# MIMXRT1064 register map
Vendor: nxp.com; File version: 1.0
CPU: CM7 r0p1, little endian, MPU, FPU, VTOR, 4 interrupt priority bits
Registers are 32-bit, read-write, reset 0x0 unless marked. A register's access mark holds for its fields unless they carry their own. Offsets are from the block's base; [hi:lo] are bit positions; {n}, {i} and the like mark numbered series.

## CSI
Base 0x402BC000; register names take the prefix CSI_
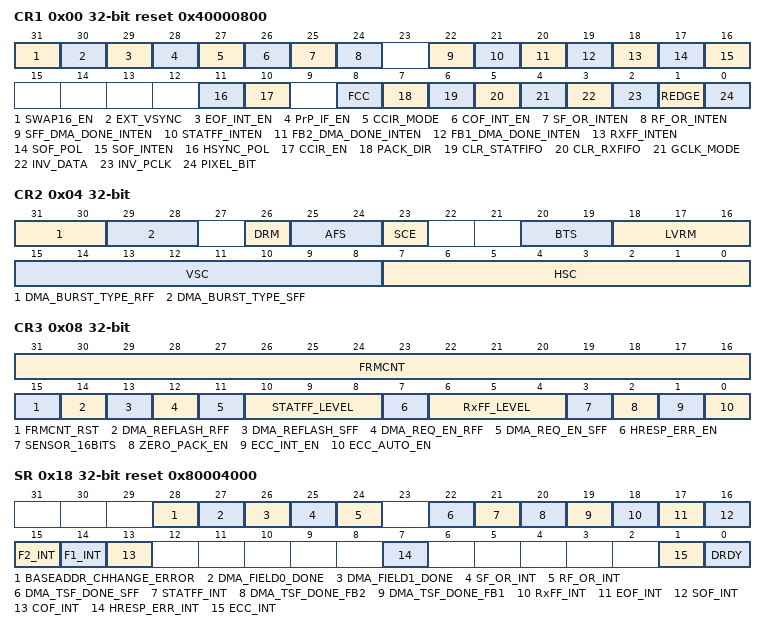
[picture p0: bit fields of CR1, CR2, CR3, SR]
0x00 CR1 reset 0x40000800 — CSI Control Register 1
  [31] SWAP16_EN — SWAP 16-Bit Enable
    0=Disable swapping; 1=Enable swapping
  [30] EXT_VSYNC — External VSYNC Enable
    0=Internal VSYNC mode; 1=External VSYNC mode
  [29] EOF_INT_EN — End-of-Frame Interrupt Enable. This bit enables and disables the EOF interrupt.
    0=EOF interrupt is disabled; 1=EOF interrupt is generated when RX count value is reached
  [28] PrP_IF_EN — CSI-PrP Interface Enable
    0=CSI to PrP bus is disabled; 1=CSI to PrP bus is enabled
  [27] CCIR_MODE — BT
    0=Progressive mode is selected; 1=Interlace mode is selected
  [26] COF_INT_EN — Change Of Image Field (COF) Interrupt Enable
    0=COF interrupt is disabled; 1=COF interrupt is enabled
  [25] SF_OR_INTEN — STAT FIFO Overrun Interrupt Enable. This bit enables the STATFIFO overrun interrupt.
    0=STATFIFO overrun interrupt is disabled; 1=STATFIFO overrun interrupt is enabled
  [24] RF_OR_INTEN — RxFIFO Overrun Interrupt Enable. This bit enables the RX FIFO overrun interrupt.
    0=RxFIFO overrun interrupt is disabled; 1=RxFIFO overrun interrupt is enabled
  [22] SFF_DMA_DONE_INTEN — STATFIFO DMA Transfer Done Interrupt Enable
    0=STATFIFO DMA Transfer Done interrupt disable; 1=STATFIFO DMA Transfer Done interrupt enable
  [21] STATFF_INTEN — STATFIFO Full Interrupt Enable. This bit enables the STAT FIFO interrupt.
    0=STATFIFO full interrupt disable; 1=STATFIFO full interrupt enable
  [20] FB2_DMA_DONE_INTEN — Frame Buffer2 DMA Transfer Done Interrupt Enable
    0=Frame Buffer2 DMA Transfer Done interrupt disable; 1=Frame Buffer2 DMA Transfer Done interrupt enable
  [19] FB1_DMA_DONE_INTEN — Frame Buffer1 DMA Transfer Done Interrupt Enable
    0=Frame Buffer1 DMA Transfer Done interrupt disable; 1=Frame Buffer1 DMA Transfer Done interrupt enable
  [18] RXFF_INTEN — RxFIFO Full Interrupt Enable. This bit enables the RxFIFO full interrupt.
    0=RxFIFO full interrupt disable; 1=RxFIFO full interrupt enable
  [17] SOF_POL — SOF Interrupt Polarity. This bit controls the condition that generates an SOF interrupt.
    0=SOF interrupt is generated on SOF falling edge; 1=SOF interrupt is generated on SOF rising edge
  [16] SOF_INTEN — Start Of Frame (SOF) Interrupt Enable. This bit enables the SOF interrupt.
    0=SOF interrupt disable; 1=SOF interrupt enable
  [11] HSYNC_POL — HSYNC Polarity Select
    0=HSYNC is active low; 1=HSYNC is active high
  [10] CCIR_EN — BT.656 Interface Enable. This bit selects the type of interface used.
    0=Traditional interface is selected; 1=BT.656 interface is selected
  [8] FCC — FIFO Clear Control
    0=Asynchronous FIFO clear is selected; 1=Synchronous FIFO clear is selected
  [7] PACK_DIR — Data Packing Direction
    0=Pack from LSB first. For image data, 0x11, 0x22, 0x33, 0x44, it will appear as 0x44332211 in RX FIFO. For stat data, 0xAAAA, 0xBBBB, it will appear as 0xBBBBAAAA in STAT FIFO.; 1=Pack from MSB first. For image data, 0x11, 0x22, 0x33, 0x44, it will appear as 0x11223344 in RX FIFO. For stat data, 0xAAAA, 0xBBBB, it will appear as 0xAAAABBBB in STAT FIFO.
  [6] CLR_STATFIFO — Asynchronous STATFIFO Clear
  [5] CLR_RXFIFO — Asynchronous RXFIFO Clear
  [4] GCLK_MODE — Gated Clock Mode Enable
    0=Non-gated clock mode. All incoming pixel clocks are valid. HSYNC is ignored.; 1=Gated clock mode. Pixel clock signal is valid only when HSYNC is active.
  [3] INV_DATA — Invert Data Input. This bit enables or disables internal inverters on the data lines.
    0=CSI_D[7:0] data lines are directly applied to internal circuitry; 1=CSI_D[7:0] data lines are inverted before applied to internal circuitry
  [2] INV_PCLK — Invert Pixel Clock Input
    0=CSI_PIXCLK is directly applied to internal circuitry; 1=CSI_PIXCLK is inverted before applied to internal circuitry
  [1] REDGE — Valid Pixel Clock Edge Select
    0=Pixel data is latched at the falling edge of CSI_PIXCLK; 1=Pixel data is latched at the rising edge of CSI_PIXCLK
  [0] PIXEL_BIT
    0=8-bit data for each pixel; 1=10-bit data for each pixel
0x04 CR2 — CSI Control Register 2
  [31:30] DMA_BURST_TYPE_RFF — Burst Type of DMA Transfer from RxFIFO. Selects the burst type of DMA transfer from RxFIFO.
    0bx0=INCR8; 1=INCR4; 3=INCR16
  [29:28] DMA_BURST_TYPE_SFF — Burst Type of DMA Transfer from STATFIFO. Selects the burst type of DMA transfer from STATFIFO.
    0bx0=INCR8; 1=INCR4; 3=INCR16
  [26] DRM — Double Resolution Mode. Controls size of statistics grid.
    0=Stats grid of 8 x 6; 1=Stats grid of 8 x 12
  [25:24] AFS — Auto Focus Spread. Selects which green pixels are used for auto-focus.
    0=Abs Diff on consecutive green pixels; 1=Abs Diff on every third green pixels; 0b1x=Abs Diff on every four green pixels
  [23] SCE — Skip Count Enable
    0=Skip count disable; 1=Skip count enable
  [20:19] BTS — Bayer Tile Start. Controls the Bayer pattern starting point.
    0=GR; 1=RG; 2=BG; 3=GB
  [18:16] LVRM — Live View Resolution Mode. Selects the grid size used for live view resolution.
    0=512 x 384; 1=448 x 336; 2=384 x 288; 3=384 x 256; 4=320 x 240; 5=288 x 216; 6=400 x 300
  [15:8] VSC — Vertical Skip Count. Contains the number of rows to skip. SCE must be 1, otherwise VSC is ignored.
    {v}=Number of rows to skip minus 1 (v=0..9)
  [7:0] HSC — Horizontal Skip Count
    {v}=Number of pixels to skip minus 1 (v=0..9)
0x08 CR3 — CSI Control Register 3
  [31:16] FRMCNT — Frame Counter
  [15] FRMCNT_RST — Frame Count Reset. Resets the Frame Counter. (Cleared automatically after reset is done)
    0=Do not reset; 1=Reset frame counter immediately
  [14] DMA_REFLASH_RFF — Reflash DMA Controller for RxFIFO
    0=No reflashing; 1=Reflash the embedded DMA controller
  [13] DMA_REFLASH_SFF — Reflash DMA Controller for STATFIFO
    0=No reflashing; 1=Reflash the embedded DMA controller
  [12] DMA_REQ_EN_RFF — DMA Request Enable for RxFIFO
    0=Disable the dma request; 1=Enable the dma request
  [11] DMA_REQ_EN_SFF — DMA Request Enable for STATFIFO
    0=Disable the dma request; 1=Enable the dma request
  [10:8] STATFF_LEVEL — STATFIFO Full Level
    0=4 Double words; 1=8 Double words; 2=12 Double words; 3=16 Double words; 4=24 Double words; 5=32 Double words; 6=48 Double words; 7=64 Double words
  [7] HRESP_ERR_EN — Hresponse Error Enable. This bit enables the hresponse (AHB protocol standard) error interrupt.
    0=Disable hresponse error interrupt; 1=Enable hresponse error interrupt
  [6:4] RxFF_LEVEL — RxFIFO Full Level
    0=4 Double words; 1=8 Double words; 2=16 Double words; 3=24 Double words; 4=32 Double words; 5=48 Double words; 6=64 Double words; 7=96 Double words
  [3] SENSOR_16BITS — 16-bit Sensor Mode
    0=Only one 8-bit sensor is connected; 1=One 16-bit sensor is connected
  [2] ZERO_PACK_EN — Dummy Zero Packing Enable
    0=Zero packing disabled; 1=Zero packing enabled
  [1] ECC_INT_EN — Error Detection Interrupt Enable
    0=No interrupt is generated when error is detected. Only the status bit ECC_INT is set.; 1=Interrupt is generated when error is detected
  [0] ECC_AUTO_EN — Automatic Error Correction Enable
    0=Auto Error correction is disabled; 1=Auto Error correction is enabled
0x0C STATFIFO ro — CSI Statistic FIFO Register
  [31:0] STAT — Static data from sensor
0x10 RFIFO ro — CSI RX FIFO Register
  [31:0] IMAGE — Received image data
0x14 RXCNT reset 0x9600 — CSI RX Count Register
  [21:0] RXCNT — RxFIFO Count
0x18 SR reset 0x80004000 — CSI Status Register
  [28] BASEADDR_CHHANGE_ERROR — When using base address switching enable, this bit will be 1 when switching occur before DMA complete
  [27] DMA_FIELD0_DONE — When DMA field 0 is complete, this bit will be set to 1(clear by writing 1).
  [26] DMA_FIELD1_DONE — When DMA field 1 is complete, this bit will be set to 1(clear by writing 1).
  [25] SF_OR_INT — STATFIFO Overrun Interrupt Status
    0=STATFIFO has not overflowed; 1=STATFIFO has overflowed
  [24] RF_OR_INT — RxFIFO Overrun Interrupt Status
    0=RXFIFO has not overflowed; 1=RXFIFO has overflowed
  [22] DMA_TSF_DONE_SFF — DMA Transfer Done from StatFIFO
    0=DMA transfer is not completed; 1=DMA transfer is completed
  [21] STATFF_INT — STATFIFO Full Interrupt Status
    0=STATFIFO is not full; 1=STATFIFO is full
  [20] DMA_TSF_DONE_FB2 — DMA Transfer Done in Frame Buffer2
    0=DMA transfer is not completed; 1=DMA transfer is completed
  [19] DMA_TSF_DONE_FB1 — DMA Transfer Done in Frame Buffer1
    0=DMA transfer is not completed; 1=DMA transfer is completed
  [18] RxFF_INT — RXFIFO Full Interrupt Status
    0=RxFIFO is not full; 1=RxFIFO is full
  [17] EOF_INT — End of Frame (EOF) Interrupt Status. Indicates when EOF is detected. (Cleared by writing 1)
    0=EOF is not detected; 1=EOF is detected
  [16] SOF_INT — Start of Frame Interrupt Status. Indicates when SOF is detected. (Cleared by writing 1)
    0=SOF is not detected; 1=SOF is detected
  [15] F2_INT — BT
    0=Field 2 of video is not detected; 1=Field 2 of video is about to start
  [14] F1_INT — BT
    0=Field 1 of video is not detected; 1=Field 1 of video is about to start
  [13] COF_INT — Change Of Field Interrupt Status
    0=Video field has no change; 1=Change of video field is detected
  [7] HRESP_ERR_INT — Hresponse Error Interrupt Status
    0=No hresponse error; 1=Hresponse error is detected
  [1] ECC_INT — BT
    0=No error detected; 1=Error is detected in BT.656 coding
  [0] DRDY — RXFIFO Data Ready
    0=No data (word) is ready; 1=At least 1 datum (word) is ready in RXFIFO
0x20 DMASA_STATFIFO — CSI DMA Start Address Register - for STATFIFO
  [31:2] DMA_START_ADDR_SFF — DMA Start Address for STATFIFO
0x24 DMATS_STATFIFO — CSI DMA Transfer Size Register - for STATFIFO
  [31:0] DMA_TSF_SIZE_SFF — DMA Transfer Size for STATFIFO
0x28 DMASA_FB1 — CSI DMA Start Address Register - for Frame Buffer1
  [31:2] DMA_START_ADDR_FB1 — DMA Start Address in Frame Buffer1
0x2C DMASA_FB2 — CSI DMA Transfer Size Register - for Frame Buffer2
  [31:2] DMA_START_ADDR_FB2 — DMA Start Address in Frame Buffer2
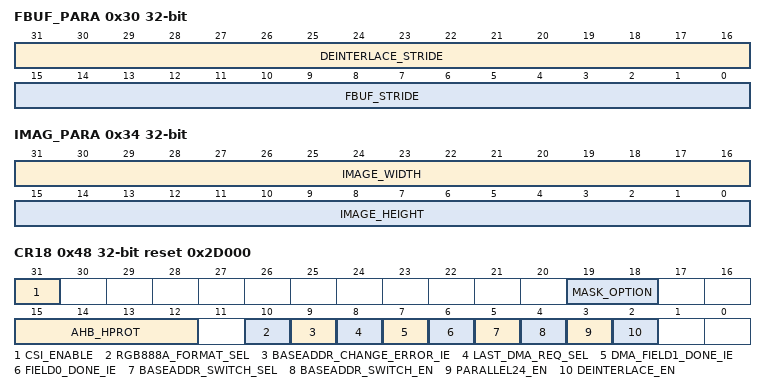
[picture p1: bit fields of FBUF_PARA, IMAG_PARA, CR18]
0x30 FBUF_PARA — CSI Frame Buffer Parameter Register
  [31:16] DEINTERLACE_STRIDE — DEINTERLACE_STRIDE is only used in the deinterlace mode
  [15:0] FBUF_STRIDE — Frame Buffer Parameter
0x34 IMAG_PARA — CSI Image Parameter Register
  [31:16] IMAGE_WIDTH — This field indicates the number of active pixel cycles per line
  [15:0] IMAGE_HEIGHT — Image Height. Indicates how many pixels in a column of the image from the sensor.
0x48 CR18 reset 0x2D000 — CSI Control Register 18
  [31] CSI_ENABLE — CSI global enable signal
  [19:18] MASK_OPTION — These bits used to choose the method to mask the CSI input.
    0=Writing to memory (OCRAM or external DDR) from first completely frame, when using this option, the CSI_ENABLE should be 1; 1=Writing to memory when CSI_ENABLE is 1; 2=Writing to memory from second completely frame, when using this option, the CSI_ENABLE should be 1; 3=Writing to memory when data comes in, not matter the CSI_ENABLE is 1 or 0
  [15:12] AHB_HPROT — Hprot value in AHB bus protocol.
  [10] RGB888A_FORMAT_SEL — Output is 32-bit format.
    0={8'h0, data[23:0]}; 1={data[23:0], 8'h0}
  [9] BASEADDR_CHANGE_ERROR_IE — Base address change error interrupt enable signal.
    0=Interrupt disabled; 1=Interrupt enabled
  [8] LAST_DMA_REQ_SEL — Choosing the last DMA request condition
    0=fifo_full_level; 1=hburst_length
  [7] DMA_FIELD1_DONE_IE — When in interlace mode, field 1 done interrupt enable.
    0=Interrupt disabled; 1=Interrupt enabled
  [6] FIELD0_DONE_IE — In interlace mode, field 0 means interrupt enabled.
    0=Interrupt disabled; 1=Interrupt enabled
  [5] BASEADDR_SWITCH_SEL — CSI 2 base addresses switching method. When using this bit, BASEADDR_SWITCH_EN is 1.
    0=Switching base address at the edge of the vsync; 1=Switching base address at the edge of the first data of each frame
  [4] BASEADDR_SWITCH_EN — When this bit is enabled, CSI DMA will switch the base address according to BASEADDR_SWITCH_SEL rather than automatically by DMA completed
  [3] PARALLEL24_EN — Enable bit for Parallel RGB888/YUV444 24bit input
    0=Input is disabled; 1=Input is enabled
  [2] DEINTERLACE_EN — This bit is used to select the output method When input is standard BT.656 video.
    0=Deinterlace disabled; 1=Deinterlace enabled
0x4C CR19 — CSI Control Register 19
  [7:0] DMA_RFIFO_HIGHEST_FIFO_LEVEL — This byte stores the highest FIFO level achieved by CSI FIFO timely and will be clear by writing 8'ff to it
